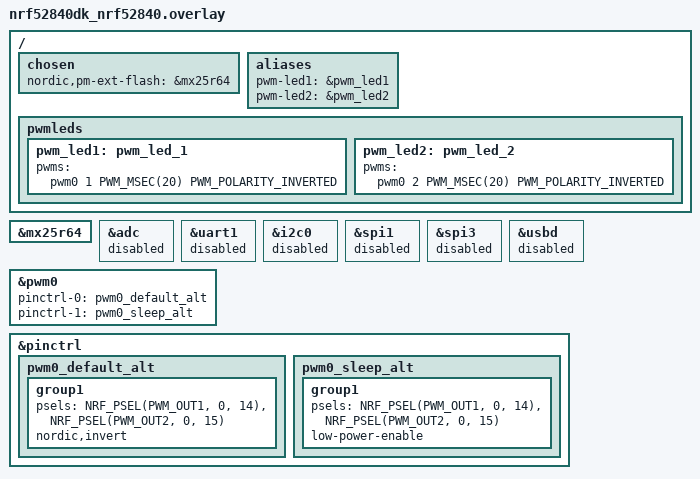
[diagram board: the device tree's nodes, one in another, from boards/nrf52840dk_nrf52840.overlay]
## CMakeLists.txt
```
#
# Smart window covering with Memfault observability over nRF Cloud CoAP.
# nRF52840 — based on the NCS matter/window_covering sample.
#

cmake_minimum_required(VERSION 3.20.0)

find_package(Zephyr HINTS $ENV{ZEPHYR_BASE})

project(blinds-nrf52840)

# Enable GNU STD support.
include(${ZEPHYR_CONNECTEDHOMEIP_MODULE_DIR}/config/nrfconnect/app/enable-gnu-std.cmake)

# Include all source files that are located in the Matter common directory.
include(${ZEPHYR_NRF_MODULE_DIR}/samples/matter/common/cmake/source_common.cmake)

# Include Data Model utils
include(${ZEPHYR_NRF_MODULE_DIR}/samples/matter/common/cmake/data_model.cmake)

include(${ZEPHYR_NRF_MODULE_DIR}/samples/matter/common/cmake/zap_helpers.cmake)
ncs_get_zap_parent_dir(ZAP_PARENT_DIR)

# src/ must be a global include so the Memfault SDK can find
# memfault_metrics_heartbeat_config.def and memfault_platform_config.h
zephyr_include_directories(src)

target_include_directories(app PRIVATE
  src
  ${ZAP_PARENT_DIR}
)

# --- Window covering application (from the NCS sample) ---
target_sources(app PRIVATE
  src/main.cpp
  src/app_task.cpp
  src/window_covering.cpp
  src/zcl_callbacks.cpp
)

# --- Observability stack ---
# Ported unchanged from openevse-nrf54l15 apart from blinds.cpp replacing the
# EVSE state source. Everything here is silicon-agnostic: OpenThread native UDP,
# mbedTLS DTLS, PSA crypto, no Zephyr IP stack.
target_sources(app PRIVATE
  src/blinds.cpp
  src/telemetry.c
  src/dtls_transport.c
  src/coap_codec.c
  src/jwt.c
  src/matter_metrics.cpp
  src/border_router.c
)

# nrfcloud_shell.c is nothing but shell command handlers, so it drops out of a
# release image entirely. jwt.c keeps its handlers behind #ifdef CONFIG_SHELL
# because the same file also holds jwt_generate_psa() and sntp_sync(), which
# the telemetry thread needs.
if(CONFIG_SHELL)
  target_sources(app PRIVATE src/nrfcloud_shell.c)
endif()

if(CONFIG_BLINDS_UDP_ECHO_SHELL)
  target_sources(app PRIVATE src/udp_echo_shell.c)
endif()

if(CONFIG_BLINDS_SIM)
  target_sources(app PRIVATE src/blinds_sim.cpp)
endif()

if(CONFIG_BLINDS_THREAD_AUTOJOIN)
  target_sources(app PRIVATE src/thread_prov.c)
endif()

if(CONFIG_PROVISIONING)
  target_sources(app PRIVATE
    src/provisioning.c
    src/provisioning_attest.cpp
    src/csr.c
  )
endif()

if(CONFIG_PROVISIONING_SHELL)
  target_sources(app PRIVATE src/provisioning_shell.c)
endif()

ncs_configure_data_model()
```

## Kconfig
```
mainmenu "Matter Window Covering with Memfault Observability (nRF52840)"

config STATE_LEDS
	bool "Use LEDs to indicate the device state"
	default y
	help
	  Use LEDs to render commissioning progress and factory reset initiation.

# Reduce Thread TX output power to 0 dBm for SED device
config OPENTHREAD_DEFAULT_TX_POWER
	default 0

menu "Observability"

config BLINDS_SIM
	bool "Simulate shade duty cycle"
	default n
	help
	  Drive the Matter WindowCovering cluster on a repeating daily schedule
	  so the blinds_* metrics carry realistic signal on a devkit with no
	  motor attached. Commands go through the same path a controller uses,
	  so the reported values are still live attribute reads.

	  Demo and pilot aid. Leave disabled in a production image.

config BLINDS_SIM_DAY_SECONDS
	int "Seconds of wall clock per simulated day"
	depends on BLINDS_SIM
	default 600
	help
	  A compressed day, so a dashboard fills with plausible duty cycle in
	  minutes rather than weeks. Four movements are spread across it.

config BLINDS_BUTTON_HEARTBEAT
	bool "Button 4 forces a heartbeat and an immediate upload"
	default y
	depends on MEMFAULT
	help
	  Collects a Memfault heartbeat and wakes the telemetry thread so the
	  chunk uploads within seconds instead of waiting out the upload
	  interval. Button 1 is the board function/factory-reset button and
	  buttons 2 and 3 are open/close, so button 4 is the free one.

	  Invaluable for demos; harmless to ship.

config BLINDS_UDP_ECHO_SHELL
	bool "UDP echo shell commands"
	default y
	depends on SHELL
	help
	  Adds 'echo ipv6' / 'echo nat64' for probing whether a given border
	  router actually routes device traffic to the internet. This is the
	  fastest way to characterise a new gateway — keep it in lab images.

config BLINDS_THREAD_AUTOJOIN
	bool "Auto-join Thread from a built-in dataset"
	default n
	help
	  Developer convenience: join a known Thread network at boot without
	  BLE commissioning. Requires a real dataset in thread_prov.c, which
	  contains the network master key — never enable for a shipped image.

endmenu

menu "Device identity provisioning"

config PROVISIONING
	bool "On-die key generation and attested CSR"
	depends on SETTINGS
	# PKCS#10 CSR construction. MBEDTLS_X509_CSR_WRITE_C alone does not
	# build: it needs X509_CREATE_C, which in turn needs OID_C,
	# ASN1_WRITE_C, PK_PARSE_C and either MD_C or USE_PSA_CRYPTO
	# (mbedtls check_config.h:1034). USE_PSA_CRYPTO is required anyway for
	# mbedtls_pk_setup_opaque(), which is what keeps the private key inside
	# PSA while the CSR is being signed.
	# No mbedTLS X.509 write selects: the CSR is encoded directly in csr.c.
	# mbedtls_x509write_csr() needed mbedtls_pk_setup_opaque() to bind a
	# non-exportable PSA key, and mbedTLS 4.x (NCS 3.4.0 onward) removed the
	# public PK module. Encoding it ourselves drops six Kconfig dependencies
	# and is immune to that churn.
	select BASE64
	help
	  Generate the nRF Cloud identity keypair inside the device and emit a
	  PKCS#10 CSR signed by the Matter DAC key, instead of compiling a
	  private key into the image. See plans/identity-provisioning.md.

if PROVISIONING

config PROVISIONING_PSA_KEY_ID
	int "PSA persistent key ID for the device identity key"
	default 305419896

config PROVISIONING_KEY_IN_KMU
	bool "Store the identity key in hardware KMU slots (nRF54L only)"
	default n
	help
	  Not available on nRF52840 — that part falls back to trusted storage
	  plus APPROTECT, which is the same protection the Matter DAC private
	  key already has. This symbol is what changes on migration to nRF54L.

config PROVISIONING_FALLBACK_KEY
	bool "Fall back to the compiled-in key in credentials.h"
	default n
	help
	  Set to n for production. With this enabled an unprovisioned unit still
	  has a usable identity, which is exactly what a shipped image must not.

config PROVISIONING_SHELL
	bool "Factory fixture shell commands"
	default y
	depends on SHELL

endif # PROVISIONING

endmenu

#
# mbedTLS DTLS client layer.
#
# nrf/subsys/net/openthread/Kconfig.defconfig forces MBEDTLS_SSL_TLS_C and
# MBEDTLS_SSL_CLI_C to 'n' unless one of OPENTHREAD_JOINER, COMMISSIONER,
# COAPS or BLE_TCAT is enabled. MBEDTLS_SSL_TLS_C is promptless, so prj.conf
# cannot raise it — the value comes purely from whichever 'default' is parsed
# first. These definitions precede the sourced NCS Kconfig files, so they win.
#
# The nRF54L project got here via CONFIG_OPENTHREAD_COAPS=y. That is not an
# option on nRF52840: the prebuilt MTD library exports no otCoapSecure symbols.
# We never use OpenThread's CoAP stack anyway — all traffic goes through the
# native UDP API — so overriding the two symbols directly is both cheaper and
# more honest about what is actually needed.
#
# NCS 3.4.0 made MBEDTLS_TLS_LIBRARY promptless as well, so it can no longer be
# set from prj.conf either. It is now selected only by the same Thread features
# listed above, by the Wi-Fi hostap_crypto stack, or by NET_SOCKETS_SOCKOPT_TLS
# (which drags in the Zephyr IP stack we deliberately avoid). On 3.2.x/3.3.x it
# still carries a prompt, so a default here is harmless there and required here.
config MBEDTLS_TLS_LIBRARY
	default y

config MBEDTLS_SSL_TLS_C
	default y

config MBEDTLS_SSL_CLI_C
	default y

# Work around an upstream defect in the NCS Memfault integration.
#
# nrf/modules/memfault-firmware-sdk/Kconfig defaults this prefix to
# "$(APP_VERSION_STRING)+", but Zephyr's kconfig.cmake exports the app version
# as APPVERSION -- APP_VERSION_STRING is never placed in the Kconfig
# environment. The reference therefore expands to nothing and every build
# reports a version of "+<build id>", losing the semantic part entirely. The
# sibling MEMFAULT_NCS_FW_VERSION uses APP_VERSION_TWEAK_STRING, which *is*
# exported, so only the AUTO path is affected.
#
# This default is evaluated before the module's because the application Kconfig
# is the top-level file. Remove it once NCS is fixed.
config MEMFAULT_NCS_FW_VERSION_PREFIX
	default "$(APPVERSION)+"

source "$(ZEPHYR_CONNECTEDHOMEIP_MODULE_DIR)/config/nrfconnect/chip-module/Kconfig.features"
source "$(ZEPHYR_CONNECTEDHOMEIP_MODULE_DIR)/config/nrfconnect/chip-module/Kconfig.defaults"
source "$(ZEPHYR_NRF_MODULE_DIR)/samples/matter/common/src/Kconfig"
source "Kconfig.zephyr"
```

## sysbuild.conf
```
#
# Copyright (c) 2024 Nordic Semiconductor
#
# SPDX-License-Identifier: LicenseRef-Nordic-5-Clause
#

SB_CONFIG_MATTER=y

# NCS 3.4.0: Matter partitions come from devicetree, not Partition Manager.
SB_CONFIG_PARTITION_MANAGER=n
```

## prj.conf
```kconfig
#
# Smart window covering with Memfault observability over nRF Cloud CoAP.
# Target: nrf52840dk/nrf52840
#
# Base configuration follows the NCS matter/window_covering sample, including
# its MTD / SSED sleepy-device topology, because that is what a real motorised
# shade is. The observability stack is layered on top unchanged.
#

# ---------------- Matter ----------------
CONFIG_CHIP=y
CONFIG_CHIP_PROJECT_CONFIG="src/chip_project_config.h"
CONFIG_CHIP_DEVICE_PRODUCT_NAME="Smart Shade"
CONFIG_NCS_SAMPLE_MATTER_ZAP_FILE_PATH="${APPLICATION_CONFIG_DIR}/src/default_zap/window-app.zap"
CONFIG_CHIP_DEVICE_PRODUCT_ID=32784
# Window Covering (0x0202). Without this the device type defaults to
# 0xFFFF, which is not a valid Matter device type and shows up wrong in
# Basic Information and the DNS-SD TXT records.
CONFIG_CHIP_DEVICE_TYPE=514
CONFIG_STD_CPP17=y

# BLE commissioning — the path a real product uses
CONFIG_CHIP_ENABLE_PAIRING_AUTOSTART=y
CONFIG_CHIP_BLE_EXT_ADVERTISING=y
CONFIG_CHIP_BLE_ADVERTISING_DURATION=60
CONFIG_BT_DEVICE_NAME="SmartShade"

# Factory data. Required for provisioning: the DAC and PAI live here, and
# provisioning_attest.cpp needs them to vouch for the CSR.
CONFIG_CHIP_FACTORY_DATA=y
CONFIG_CHIP_FACTORY_DATA_BUILD=y

# ---------------- Thread: sleepy end device ----------------
# A shade is battery or mains-with-low-duty-cycle, not a router. MTD keeps both
# the OpenThread library and the RAM footprint smaller than FTD.
CONFIG_OPENTHREAD_NORDIC_LIBRARY_MTD=y
CONFIG_OPENTHREAD_MTD=y
CONFIG_OPENTHREAD_FTD=n
CONFIG_CHIP_ENABLE_ICD_SUPPORT=y
CONFIG_CHIP_THREAD_SSED=y
CONFIG_CHIP_ICD_SLOW_POLL_INTERVAL=500
CONFIG_CHIP_ICD_FAST_POLLING_INTERVAL=500

# DNS client, for resolving nRF Cloud and the SNTP server through the border
# router. Verified present in the nRF52840 MTD prebuilt library.
CONFIG_OPENTHREAD_DNS_CLIENT=y

CONFIG_PWM=y
CONFIG_DK_LIBRARY=y
CONFIG_PM_DEVICE=y
CONFIG_IEEE802154_NRF5_RX_STACK_SIZE=1024
CONFIG_THREAD_NAME=y
CONFIG_MPU_STACK_GUARD=y
CONFIG_RESET_ON_FATAL_ERROR=n

# ---------------- Shell (lab build) ----------------
CONFIG_CHIP_LIB_SHELL=y
CONFIG_NCS_SAMPLE_MATTER_TEST_SHELL=y
CONFIG_OPENTHREAD_SHELL=y
CONFIG_SHELL_STACK_SIZE=10240
CONFIG_SHELL_CMD_BUFF_SIZE=512
CONFIG_USE_SEGGER_RTT=n
CONFIG_CHIP_NFC_ONBOARDING_PAYLOAD=n

# ---------------- DTLS transport ----------------
# NOTE: the nRF54L project reached this config via CONFIG_OPENTHREAD_COAPS=y,
# which is NOT usable here — the nRF52840 MTD prebuilt library exports no
# otCoapSecure symbols. The mbedTLS DTLS client is therefore selected directly.
# We never use OpenThread's CoAP stack anyway; this only ever supplied the
# mbedTLS configuration.
CONFIG_MBEDTLS=y
# MBEDTLS_TLS_LIBRARY is NOT set here: NCS 3.4.0 made it promptless, so
# assigning it in prj.conf is a hard Kconfig error. It is forced on in
# Kconfig instead, which works on 3.2.x, 3.3.x and 3.4.x alike.
CONFIG_MBEDTLS_SSL_PROTO_DTLS=y
# MBEDTLS_SSL_TLS_C / SSL_CLI_C are forced on in Kconfig — see the comment
# there. No SSL_SRV_C or SSL_COOKIE_C: this is a client only.
CONFIG_MBEDTLS_MD_C=y
CONFIG_MBEDTLS_KEY_EXCHANGE_ECDHE_ECDSA_ENABLED=y
# The nRF Cloud root CA in credentials.h is a PEM string. nrf_security leaves
# PEM_PARSE_C off under NCS 3.4.0, so mbedtls_x509_crt_parse() reads the PEM
# text as DER and fails with -0x2180 (X509_INVALID_FORMAT).
CONFIG_MBEDTLS_PEM_PARSE_C=y

# DTLS Connection ID (RFC 9146) — required by nRF Cloud CoAP
CONFIG_MBEDTLS_SSL_DTLS_CONNECTION_ID=y

# Handshake buffers. The 900-byte default cannot hold nRF Cloud's server cert.
CONFIG_MBEDTLS_SSL_IN_CONTENT_LEN=1500
CONFIG_MBEDTLS_SSL_OUT_CONTENT_LEN=900
CONFIG_MBEDTLS_HEAP_SIZE=20480

CONFIG_BASE64=y

# ---------------- Device identity provisioning ----------------
CONFIG_PROVISIONING=y
CONFIG_PROVISIONING_SHELL=y
# Lab devices only. Production images must set this to n.
CONFIG_PROVISIONING_FALLBACK_KEY=n
# nRF54L only — the one symbol that changes on migration.
# CONFIG_PROVISIONING_KEY_IN_KMU=y

# Persistent PSA keys need an encrypted ITS backend. nRF52840 has no TF-M, so
# this is the trusted_storage library rather than a secure partition.
CONFIG_SETTINGS=y
CONFIG_TRUSTED_STORAGE=y

# ---------------- Observability ----------------
CONFIG_BLINDS_UDP_ECHO_SHELL=y
CONFIG_BLINDS_THREAD_AUTOJOIN=n

CONFIG_MEMFAULT=y
CONFIG_MEMFAULT_SHELL=y
CONFIG_MEMFAULT_METRICS=y
CONFIG_MEMFAULT_LOGGING_ENABLE=n
CONFIG_MEMFAULT_NCS_PROJECT_KEY="YOUR_MEMFAULT_PROJECT_KEY"
# Firmware version: generated, not hand-maintained.
#
# MEMFAULT_NCS_FW_VERSION_AUTO reports "<APP_VERSION_STRING>+<build id prefix>",
# e.g. "0.2.0+fd7322", taking the semantic part from the VERSION file and the
# suffix from the GNU build ID. Four builds in two days previously all reported
# "0.1.0", including firmware that crash-looped every heartbeat and firmware
# that did not, which makes any crash-free-hours comparison across that boundary
# meaningless. Bump VERSION for a release; the build ID distinguishes every
# build in between for free.
CONFIG_MEMFAULT_NCS_FW_VERSION_AUTO=y
# Device ID and hardware version are board-specific: see boards/<board>.conf.
CONFIG_MEMFAULT_NCS_FW_TYPE="blinds-matter-software"
CONFIG_MEMFAULT_METRICS_MEMORY_USAGE=n
CONFIG_MEMFAULT_METRICS_SYNC_SUCCESS=n
CONFIG_MEMFAULT_METRICS_CONNECTIVITY_CONNECTED_TIME=n
CONFIG_MEMFAULT_METRICS_BLUETOOTH=n
CONFIG_MEMFAULT_NCS_IMPLEMENT_METRICS_COLLECTION=n

# Coredump lives in RAM. 4 KB rather than the nRF54L project's 8 KB — RAM is
# the scarce resource on a 256 KB part. Revisit once the real figure is known;
# a flash-backed coredump in the external QSPI is the alternative.
CONFIG_MEMFAULT_RAM_BACKED_COREDUMP=y
CONFIG_MEMFAULT_RAM_BACKED_COREDUMP_SIZE=4096

# Heartbeat every 30 min; a shade's state changes slowly and radio time is
# the dominant energy cost on a sleepy device.
# 300 s for the pilot: denser dashboards for demos. Raise for production —
# the energy cost per heartbeat is still unmeasured.
# Heartbeat collection reaches into OpenThread and the CHIP stack. The stock
# Zephyr port runs the collect callback on the system workqueue (1120-byte
# stack here), which overflows and faults instead of emitting a heartbeat.
# telemetry.c supplies the timer instead and collects on its own 8 KB thread.
CONFIG_MEMFAULT_METRICS_TIMER_CUSTOM=y
CONFIG_MEMFAULT_METRICS_HEARTBEAT_INTERVAL_SECS=300

# ---------------- Logging ----------------
CONFIG_LOG=y
CONFIG_LOG_MODE_DEFERRED=y
CONFIG_CHIP_APP_LOG_LEVEL=3
CONFIG_MATTER_LOG_LEVEL_INF=y

# ---------------- nRF52840 external flash ----------------
# The MCUboot secondary slot lives in the QSPI part, which is what frees the
# app slot to 959 KB. Also the natural home for a flash-backed coredump.
CONFIG_NORDIC_QSPI_NOR=y
CONFIG_NORDIC_QSPI_NOR_FLASH_LAYOUT_PAGE_SIZE=4096
CONFIG_STREAM_FLASH=y
CONFIG_IMG_MANAGER=y
CONFIG_MCUBOOT_IMG_MANAGER=y

# Simulated shade duty cycle so the blinds_* metrics carry signal on a DK.
CONFIG_BLINDS_SIM=y
```

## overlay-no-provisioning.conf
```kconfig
# Observability only, no on-die identity provisioning.
# Use with the base prj.conf to measure what the CSR/X509-write machinery costs:
#   west build -- -DEXTRA_CONF_FILE=overlay-no-provisioning.conf
CONFIG_PROVISIONING=n
CONFIG_PROVISIONING_SHELL=n
```

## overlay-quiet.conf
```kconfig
#
# Quiet the device for tooling that drives the shell.
#
# provision.py reads a command's output until the link goes idle. The blinds
# simulation logs every cluster write continuously, so the link never goes
# idle, the 'OK' is buried in a flood of ZCL traffic and provisioning fails
# with a misleading "did not emit" error. Provisioning is a factory step and
# the simulation has no business running during it.
#
CONFIG_BLINDS_SIM=n

# Let the shell change log levels at runtime, so the next person has a way out
# without a rebuild.
CONFIG_LOG_CMDS=y
```

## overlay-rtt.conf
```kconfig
#
# Console and shell over SEGGER RTT instead of the board UART.
#
# The nRF5340-DK's Interface MCU stopped passing VCOM traffic: the app core
# demonstrably transmits (UARTE0 EVENTS_TXSTARTED and EVENTS_ENDTX both set,
# PSEL.TXD = P0.20 as the devicetree specifies) but the host receives nothing
# on either virtual COM port. RTT rides the debug probe's memory access, which
# still works, so this gets a console back without waiting on a probe firmware
# repair.
#
# Layer it on:
#   west build -b nrf5340dk/nrf5340/cpuapp -- -DEXTRA_CONF_FILE=overlay-rtt.conf
#
CONFIG_USE_SEGGER_RTT=y
CONFIG_RTT_CONSOLE=y
CONFIG_UART_CONSOLE=n

# The standalone RTT log backend and the RTT shell backend both claim RTT
# channel 0, which is a build-time assertion failure. Let logs ride the shell's
# own log backend instead -- the same arrangement the UART console used.
CONFIG_LOG_BACKEND_RTT=n
CONFIG_LOG_BACKEND_UART=n
CONFIG_SHELL_LOG_BACKEND=y

CONFIG_SHELL_BACKEND_SERIAL=n
CONFIG_SHELL_BACKEND_RTT=y

# RTT defaults to SEGGER_RTT_MODE_NO_BLOCK_SKIP: when the up-buffer fills it
# discards output rather than waiting. That is invisible for logging but
# corrupts anything used as a data channel -- provision.py's attested CSR
# bundle (DAC, PAI, CSR and signature, several KB emitted in one burst) came
# back with whole blocks missing, which surfaces as the same misleading
# "device did not emit" error as a malformed argument.
#
# Blocking mode stalls the firmware whenever no host is draining RTT, so this
# belongs to a bench image only. Never ship it.
CONFIG_SEGGER_RTT_MODE_BLOCK_IF_FIFO_FULL=y
CONFIG_SEGGER_RTT_BUFFER_SIZE_UP=8192

# The host->target buffer defaults to 16 bytes, against a 512-byte shell command
# buffer. The RTT down-channel has no flow control back to the host, so a line
# written in one burst is simply truncated at 16 characters: "provision status"
# arrives as "provision sta". That surfaces as "Please specify a subcommand" or,
# worse, as a command that silently does something else. 'provision keygen' is
# exactly 16 characters, which is why it was the only step that ever worked.
# Match the shell buffer.
CONFIG_SEGGER_RTT_BUFFER_SIZE_DOWN=512
```

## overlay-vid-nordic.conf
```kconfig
# Diagnostic overlay: advertise Nordic's real CSA vendor ID (0x1915 = 6421) in
# place of the Matter test VID 0xFFF1 (65521), to establish whether an ecosystem
# refuses this device before opening a BLE connection purely on a vendor-ID
# lookup.
#
# Nordic permits use of its VID without guarantees, which is why this uses
# 0x1915 rather than an unrelated certified vendor's ID.
#
# The SDK only ships development DACs for VID 0xFFF1, and a real vendor's DAC
# would have to chain to that vendor's PAA, so the attestation credentials are
# pinned explicitly to the FFF1-8010 development set rather than letting the
# factory data generator look up a (nonexistent) 1915-8010 pair.
#
# The result is deliberately inconsistent: the advertisement, QR payload and
# Basic Information cluster all report 0x1915 while the DAC still attests
# 0xFFF1, so device attestation WILL fail once a commissioner connects. That is
# expected and does not invalidate the test -- the signal is whether a CHIPoBLE
# connection is opened at all, not whether commissioning completes.
#
# Bench diagnostic only. Never ship this.
CONFIG_CHIP_DEVICE_VENDOR_ID=6421

CONFIG_CHIP_FACTORY_DATA_CERT_SOURCE_USER=y
CONFIG_CHIP_FACTORY_DATA_USER_CERTS_DAC_CERT="/opt/nordic/ncs/v3.4.0/modules/lib/matter/credentials/development/attestation/Matter-Development-DAC-FFF1-8010-Cert.der"
CONFIG_CHIP_FACTORY_DATA_USER_CERTS_DAC_KEY="/opt/nordic/ncs/v3.4.0/modules/lib/matter/credentials/development/attestation/Matter-Development-DAC-FFF1-8010-Key.der"
CONFIG_CHIP_FACTORY_DATA_USER_CERTS_PAI_CERT="/opt/nordic/ncs/v3.4.0/modules/lib/matter/credentials/development/attestation/Matter-Development-PAI-FFF1-noPID-Cert.der"
```

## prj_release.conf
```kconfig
#
# Production image. Same application and observability stack as prj.conf, with
# every development affordance removed.
#
# Note on provisioning: PROVISIONING stays enabled (the device still needs its
# on-die key and JWT signing) but PROVISIONING_SHELL is off, so a fielded unit
# cannot be asked to re-key over a console. Factory provisioning therefore runs
# against a separate build that keeps the shell — see
# plans/identity-provisioning.md.
#

# ---------------- Matter ----------------
CONFIG_CHIP=y
CONFIG_CHIP_PROJECT_CONFIG="src/chip_project_config.h"
CONFIG_CHIP_DEVICE_PRODUCT_NAME="Smart Shade"
CONFIG_NCS_SAMPLE_MATTER_ZAP_FILE_PATH="${APPLICATION_CONFIG_DIR}/src/default_zap/window-app.zap"
CONFIG_CHIP_DEVICE_PRODUCT_ID=32784
# Window Covering (0x0202). Without this the device type defaults to
# 0xFFFF, which is not a valid Matter device type and shows up wrong in
# Basic Information and the DNS-SD TXT records.
CONFIG_CHIP_DEVICE_TYPE=514
CONFIG_STD_CPP17=y
CONFIG_CHIP_ENABLE_PAIRING_AUTOSTART=y
CONFIG_CHIP_BLE_EXT_ADVERTISING=y
CONFIG_CHIP_BLE_ADVERTISING_DURATION=60
CONFIG_BT_DEVICE_NAME="SmartShade"
CONFIG_CHIP_FACTORY_DATA=y
CONFIG_CHIP_FACTORY_DATA_BUILD=y
CONFIG_CHIP_NFC_ONBOARDING_PAYLOAD=n

# ---------------- Thread: sleepy end device ----------------
CONFIG_OPENTHREAD_NORDIC_LIBRARY_MTD=y
CONFIG_OPENTHREAD_MTD=y
CONFIG_OPENTHREAD_FTD=n
CONFIG_CHIP_ENABLE_ICD_SUPPORT=y
CONFIG_CHIP_THREAD_SSED=y
CONFIG_CHIP_ICD_SLOW_POLL_INTERVAL=500
CONFIG_CHIP_ICD_FAST_POLLING_INTERVAL=500
CONFIG_OPENTHREAD_DNS_CLIENT=y

CONFIG_PWM=y
CONFIG_DK_LIBRARY=y
CONFIG_PM_DEVICE=y
CONFIG_RAM_POWER_DOWN_LIBRARY=y
CONFIG_IEEE802154_NRF5_RX_STACK_SIZE=1024
CONFIG_MPU_STACK_GUARD=y
CONFIG_RESET_ON_FATAL_ERROR=y
CONFIG_NCS_SAMPLE_MATTER_WATCHDOG=y

# ---------------- DTLS transport ----------------
CONFIG_MBEDTLS=y
CONFIG_MBEDTLS_TLS_LIBRARY=y
CONFIG_MBEDTLS_MD_C=y
CONFIG_MBEDTLS_SSL_PROTO_DTLS=y
CONFIG_MBEDTLS_KEY_EXCHANGE_ECDHE_ECDSA_ENABLED=y
# The nRF Cloud root CA in credentials.h is a PEM string. nrf_security leaves
# PEM_PARSE_C off under NCS 3.4.0, so mbedtls_x509_crt_parse() reads the PEM
# text as DER and fails with -0x2180 (X509_INVALID_FORMAT).
CONFIG_MBEDTLS_PEM_PARSE_C=y
CONFIG_MBEDTLS_SSL_DTLS_CONNECTION_ID=y
CONFIG_MBEDTLS_SSL_IN_CONTENT_LEN=1500
CONFIG_MBEDTLS_SSL_OUT_CONTENT_LEN=900
CONFIG_MBEDTLS_HEAP_SIZE=20480
CONFIG_BASE64=y

# ---------------- Identity ----------------
CONFIG_PROVISIONING=y
CONFIG_PROVISIONING_SHELL=n
CONFIG_PROVISIONING_FALLBACK_KEY=n
CONFIG_SETTINGS=y
CONFIG_TRUSTED_STORAGE=y

# ---------------- Observability ----------------
CONFIG_BLINDS_UDP_ECHO_SHELL=n
CONFIG_BLINDS_THREAD_AUTOJOIN=n

CONFIG_MEMFAULT=y
CONFIG_MEMFAULT_SHELL=n
CONFIG_MEMFAULT_METRICS=y
CONFIG_MEMFAULT_LOGGING_ENABLE=n
CONFIG_MEMFAULT_NCS_PROJECT_KEY="YOUR_MEMFAULT_PROJECT_KEY"
# Firmware version: generated, not hand-maintained.
#
# MEMFAULT_NCS_FW_VERSION_AUTO reports "<APP_VERSION_STRING>+<build id prefix>",
# e.g. "0.2.0+fd7322", taking the semantic part from the VERSION file and the
# suffix from the GNU build ID. Four builds in two days previously all reported
# "0.1.0", including firmware that crash-looped every heartbeat and firmware
# that did not, which makes any crash-free-hours comparison across that boundary
# meaningless. Bump VERSION for a release; the build ID distinguishes every
# build in between for free.
CONFIG_MEMFAULT_NCS_FW_VERSION_AUTO=y
# Device ID and hardware version are board-specific: see boards/<board>.conf.
CONFIG_MEMFAULT_NCS_FW_TYPE="blinds-matter-software"
CONFIG_MEMFAULT_METRICS_MEMORY_USAGE=n
CONFIG_MEMFAULT_METRICS_SYNC_SUCCESS=n
CONFIG_MEMFAULT_METRICS_CONNECTIVITY_CONNECTED_TIME=n
CONFIG_MEMFAULT_METRICS_BLUETOOTH=n
CONFIG_MEMFAULT_NCS_IMPLEMENT_METRICS_COLLECTION=n
CONFIG_MEMFAULT_RAM_BACKED_COREDUMP=y
CONFIG_MEMFAULT_RAM_BACKED_COREDUMP_SIZE=4096
# Heartbeat collection reaches into OpenThread and the CHIP stack. The stock
# Zephyr port runs the collect callback on the system workqueue (1120-byte
# stack here), which overflows and faults instead of emitting a heartbeat.
# telemetry.c supplies the timer instead and collects on its own 8 KB thread.
CONFIG_MEMFAULT_METRICS_TIMER_CUSTOM=y
CONFIG_MEMFAULT_METRICS_HEARTBEAT_INTERVAL_SECS=1800

# ---------------- Strip development affordances ----------------
CONFIG_CHIP_LIB_SHELL=n
CONFIG_NCS_SAMPLE_MATTER_TEST_SHELL=n
CONFIG_OPENTHREAD_SHELL=n
CONFIG_SHELL=n
CONFIG_CONSOLE=n
CONFIG_UART_CONSOLE=n
CONFIG_SERIAL=n
CONFIG_LOG=n
CONFIG_PRINTK=n
CONFIG_BOOT_BANNER=n
CONFIG_THREAD_NAME=n
CONFIG_ASSERT_VERBOSE=n
CONFIG_ASSERT_NO_FILE_INFO=y
CONFIG_USE_SEGGER_RTT=n

# LTO is deliberately OFF, unlike the NCS window_covering release config.
#
# The Memfault Zephyr port hooks fault handling through linker symbol
# interposition — -Wl,--wrap=z_arm_fault, --wrap=z_fatal_error, --wrap=main and
# others (ports/zephyr/common/CMakeLists.txt, ports/zephyr/panics/CMakeLists.txt).
# LTO internalises those symbols, so the linker can no longer interpose and the
# build dies with 'undefined reference to z_arm_fault' and
# 'undefined reference to __wrap_z_fatal_error'.
#
# Coredump capture is the whole point of the exercise, so LTO loses.
# CONFIG_LTO=y
CONFIG_ISR_TABLES_LOCAL_DECLARATION=y

# ---------------- nRF52840 external flash ----------------
CONFIG_NORDIC_QSPI_NOR=y
CONFIG_NORDIC_QSPI_NOR_FLASH_LAYOUT_PAGE_SIZE=4096
CONFIG_STREAM_FLASH=y
CONFIG_IMG_MANAGER=y
CONFIG_MCUBOOT_IMG_MANAGER=y
```

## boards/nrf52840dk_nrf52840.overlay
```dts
/* Copyright (c) 2021 Nordic Semiconductor ASA
 *
 * SPDX-License-Identifier: LicenseRef-Nordic-5-Clause
 */

/*
 * NCS 3.4.0 declares the Matter partition layout in devicetree rather than
 * Partition Manager. The addresses are identical to what
 * pm_static_nrf52840dk_nrf52840.yml declared on 3.2.x/3.3.x — only the
 * mechanism changed. For 3.2.x/3.3.x use -DFILE_SUFFIX=ncs32.
 */
#include <samples/matter/nrf52840_partitions.dtsi>

/ {
	chosen {
		nordic,pm-ext-flash = &mx25r64;
	};
};

&mx25r64 {
	status = "okay";
};

/ {
	/*
	 * Configure LED2 and LED3 to show the state of the
	 * window cover,by using the LED's brightness level.
	 */
	aliases {
		pwm-led1 = &pwm_led1;
		pwm-led2 = &pwm_led2;
	};

	pwmleds {
		pwm_led1: pwm_led_1 {
			pwms = <&pwm0 1 PWM_MSEC(20) PWM_POLARITY_INVERTED>;
		};

		pwm_led2: pwm_led_2 {
			pwms = <&pwm0 2 PWM_MSEC(20) PWM_POLARITY_INVERTED>;
		};
	};
};

/* Disable unused peripherals to reduce power consumption */
&adc {
	status = "disabled";
};

&uart1 {
	status = "disabled";
};

&i2c0 {
	status = "disabled";
};

&spi1 {
	status = "disabled";
};

&spi3 {
	status = "disabled";
};

&usbd {
	status = "disabled";
};

&pwm0 {
	pinctrl-0 = <&pwm0_default_alt>;
	pinctrl-1 = <&pwm0_sleep_alt>;
	pinctrl-names = "default", "sleep";
};

&pinctrl {
	pwm0_default_alt: pwm0_default_alt {
		group1 {
			psels = <NRF_PSEL(PWM_OUT1, 0, 14)>, <NRF_PSEL(PWM_OUT2, 0, 15)>;
			nordic,invert;
		};
	};

	pwm0_sleep_alt: pwm0_sleep_alt {
		group1 {
			psels = <NRF_PSEL(PWM_OUT1, 0, 14)>, <NRF_PSEL(PWM_OUT2, 0, 15)>;
			low-power-enable;
		};
	};
};
```

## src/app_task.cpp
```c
/*
 * Copyright (c) 2022 Nordic Semiconductor ASA
 *
 * SPDX-License-Identifier: LicenseRef-Nordic-5-Clause
 */

#include "app_task.h"

#include "window_covering.h"
#include "matter_metrics.h"
#ifdef CONFIG_BLINDS_BUTTON_HEARTBEAT
#include "telemetry.h"
#include <memfault/metrics/metrics.h>
#endif

#include "app/matter_init.h"
#include "app/task_executor.h"
#include "clusters/identify.h"

#include <setup_payload/OnboardingCodesUtil.h>

#include <zephyr/logging/log.h>

LOG_MODULE_DECLARE(app, CONFIG_CHIP_APP_LOG_LEVEL);

using namespace ::chip;
using namespace ::chip::app;
using namespace ::chip::DeviceLayer;

namespace
{
Nrf::Matter::IdentifyCluster sIdentifyCluster(WindowCovering::Endpoint());

#define OPEN_BUTTON_MASK DK_BTN2_MSK
#define CLOSE_BUTTON_MASK DK_BTN3_MSK

/*
 * Button 1 is the board library's function/factory-reset button and buttons 2
 * and 3 are open/close, so button 4 is the one left. It forces a heartbeat and
 * wakes the telemetry thread, which turns a demo from "wait out the upload
 * interval" into "press this and watch the dashboard".
 */
#ifdef CONFIG_BLINDS_BUTTON_HEARTBEAT
#define HEARTBEAT_BUTTON_MASK DK_BTN4_MSK
#endif
} /* namespace */

void AppTask::ButtonEventHandler(Nrf::ButtonState state, Nrf::ButtonMask hasChanged)
{
	if (OPEN_BUTTON_MASK & hasChanged) {
		WindowButtonAction action =
			(OPEN_BUTTON_MASK & state) ? WindowButtonAction::Pressed : WindowButtonAction::Released;
		Nrf::PostTask([action] { OpenHandler(action); });
	}

#ifdef CONFIG_BLINDS_BUTTON_HEARTBEAT
	if ((HEARTBEAT_BUTTON_MASK & hasChanged) && (HEARTBEAT_BUTTON_MASK & state)) {
		/*
		 * Collection reaches into OpenThread and the CHIP stack, and
		 * this runs on the system workqueue, so hand it to the
		 * telemetry thread rather than doing it here.
		 */
		telemetry_request_heartbeat();
		LOG_INF("Heartbeat triggered by button; uploading now");
	}
#endif

	if (CLOSE_BUTTON_MASK & hasChanged) {
		WindowButtonAction action =
			(CLOSE_BUTTON_MASK & state) ? WindowButtonAction::Pressed : WindowButtonAction::Released;
		Nrf::PostTask([action] { CloseHandler(action); });
	}
}

void AppTask::OpenHandler(const WindowButtonAction &action)
{
	if (action == WindowButtonAction::Pressed) {
		Instance().mOpenButtonIsPressed = true;
		if (Instance().mCloseButtonIsPressed) {
			Instance().ToggleMoveType();
		}
	} else {
		if (!Instance().mCloseButtonIsPressed) {
			if (!Instance().mMoveTypeRecentlyChanged) {
				WindowCovering::Instance().SetSingleStepTarget(OperationalState::MovingUpOrOpen);
			} else {
				Instance().mMoveTypeRecentlyChanged = false;
			}
		}
		Instance().mOpenButtonIsPressed = false;
	}
}

void AppTask::CloseHandler(const WindowButtonAction &action)
{
	if (action == WindowButtonAction::Pressed) {
		Instance().mCloseButtonIsPressed = true;
		if (Instance().mOpenButtonIsPressed) {
			Instance().ToggleMoveType();
		}
	} else {
		if (!Instance().mOpenButtonIsPressed) {
			if (!Instance().mMoveTypeRecentlyChanged) {
				WindowCovering::Instance().SetSingleStepTarget(OperationalState::MovingDownOrClose);
			} else {
				Instance().mMoveTypeRecentlyChanged = false;
			}
		}
		Instance().mCloseButtonIsPressed = false;
	}
}

void AppTask::ToggleMoveType()
{
	if (WindowCovering::Instance().GetMoveType() == WindowCovering::MoveType::LIFT) {
		WindowCovering::Instance().SetMoveType(WindowCovering::MoveType::TILT);
		LOG_INF("Window covering move: tilt");
	} else {
		WindowCovering::Instance().SetMoveType(WindowCovering::MoveType::LIFT);
		LOG_INF("Window covering move: lift");
	}
	mMoveTypeRecentlyChanged = true;
}

CHIP_ERROR AppTask::Init()
{
	/* Initialize Matter stack */
	ReturnErrorOnFailure(Nrf::Matter::PrepareServer(Nrf::Matter::InitData{ .mPostServerInitClbk = [] {
		WindowCovering::Instance().PositionLEDUpdate(WindowCovering::MoveType::LIFT);
		WindowCovering::Instance().PositionLEDUpdate(WindowCovering::MoveType::TILT);
		return CHIP_NO_ERROR;
	} }));

	if (!Nrf::GetBoard().Init(ButtonEventHandler)) {
		LOG_ERR("User interface initialization failed.");
		return CHIP_ERROR_INCORRECT_STATE;
	}

	/* Register Matter event handler that controls the connectivity status LED based on the captured Matter network
	 * state. */
	ReturnErrorOnFailure(Nrf::Matter::RegisterEventHandler(Nrf::Board::DefaultMatterEventHandler, 0));

	ReturnErrorOnFailure(sIdentifyCluster.Init());

	/*
	 * Thread/Matter diagnostics collection. Registers the event handler that
	 * counts commissioning completions and, at heartbeat time, snapshots
	 * fabric health and the administrator's vendor ID — the field that lets
	 * fleet metrics be sliced by ecosystem.
	 */
	matter_metrics_init();

	return Nrf::Matter::StartServer();
}

CHIP_ERROR AppTask::StartApp()
{
	ReturnErrorOnFailure(Init());

	while (true) {
		Nrf::DispatchNextTask();
	}

	return CHIP_NO_ERROR;
}
```

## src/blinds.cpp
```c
/*
 * Copyright (c) 2026 Jon Sharp
 *
 * SPDX-License-Identifier: Apache-2.0
 */

/*
 * Observability view of the window covering — reads live Matter attributes.
 * See blinds.h.
 */

#include "blinds.h"

#include <zephyr/kernel.h>
#include <zephyr/sys/atomic.h>

#include <platform/CHIPDeviceLayer.h>
#include <app/clusters/window-covering-server/window-covering-server.h>
#include <app-common/zap-generated/attributes/Accessors.h>

using namespace chip;
using namespace chip::app::Clusters;
using chip::Protocols::InteractionModel::Status;

namespace {

constexpr EndpointId kCoveringEndpoint = 1;

atomic_t s_move_count;
atomic_t s_stall_count;

/*
 * Position attributes are nullable: null means the covering does not know
 * where it is. That is a meaningful state rather than an error, so it is
 * reported as UINT16_MAX instead of being coerced to 0.
 */
uint16_t ReadPercent100ths(
	Status (*getter)(EndpointId, app::DataModel::Nullable<Percent100ths> &))
{
	app::DataModel::Nullable<Percent100ths> value;

	if (getter(kCoveringEndpoint, value) != Status::Success || value.IsNull()) {
		return UINT16_MAX;
	}

	return value.Value();
}

blinds_motion_t DecodeMotion(uint8_t status, uint8_t shift)
{
	/* OperationalStatus packs global/lift/tilt into 2-bit fields. */
	switch ((status >> shift) & 0x03) {
	case 1:
		return BLINDS_MOTION_OPENING;
	case 2:
		return BLINDS_MOTION_CLOSING;
	default:
		return BLINDS_MOTION_STALLED;
	}
}

} /* namespace */

void blinds_get_data(struct blinds_data *out)
{
	if (out == nullptr) {
		return;
	}

	*out = {};
	out->lift_position = UINT16_MAX;
	out->tilt_position = UINT16_MAX;
	out->lift_target = UINT16_MAX;
	out->tilt_target = UINT16_MAX;

	DeviceLayer::PlatformMgr().LockChipStack();

	out->lift_position =
		ReadPercent100ths(WindowCovering::Attributes::CurrentPositionLiftPercent100ths::Get);
	out->tilt_position =
		ReadPercent100ths(WindowCovering::Attributes::CurrentPositionTiltPercent100ths::Get);
	out->lift_target =
		ReadPercent100ths(WindowCovering::Attributes::TargetPositionLiftPercent100ths::Get);
	out->tilt_target =
		ReadPercent100ths(WindowCovering::Attributes::TargetPositionTiltPercent100ths::Get);

	BitMask<WindowCovering::OperationalStatus> status;
	if (WindowCovering::Attributes::OperationalStatus::Get(kCoveringEndpoint, &status) ==
	    Status::Success) {
		out->lift_motion = DecodeMotion(status.Raw(), 2);
		out->tilt_motion = DecodeMotion(status.Raw(), 4);
	}

	BitMask<WindowCovering::ConfigStatus> config;
	if (WindowCovering::Attributes::ConfigStatus::Get(kCoveringEndpoint, &config) ==
	    Status::Success) {
		out->config_status = config.Raw();
		/* LiftPositionAware — set once the covering knows where it is. A
		 * unit that loses calibration in the field becomes a support
		 * call, so it is worth reporting on every heartbeat. */
		out->calibrated =
			config.Has(WindowCovering::ConfigStatus::kLiftPositionAware);
	}

	BitMask<WindowCovering::Mode> mode;
	if (WindowCovering::Attributes::Mode::Get(kCoveringEndpoint, &mode) == Status::Success) {
		out->mode = mode.Raw();
	}

	DeviceLayer::PlatformMgr().UnlockChipStack();
}

uint32_t blinds_take_move_count(void)
{
	return (uint32_t)atomic_set(&s_move_count, 0);
}

uint32_t blinds_take_stall_count(void)
{
	return (uint32_t)atomic_set(&s_stall_count, 0);
}

void blinds_record_move_start(void)
{
	atomic_inc(&s_move_count);
}

void blinds_record_stall(void)
{
	atomic_inc(&s_stall_count);
}
```

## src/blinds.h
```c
/*
 * Copyright (c) 2026 Jon Sharp
 *
 * SPDX-License-Identifier: Apache-2.0
 */

#pragma once

#include <stdint.h>
#include <stdbool.h>

#ifdef __cplusplus
extern "C" {
#endif

/*
 * Observability view of the window covering.
 *
 * Values are read from the live Matter WindowCovering cluster attributes
 * rather than from a simulation, so what Memfault reports is exactly what a
 * Matter controller sees. On a real product this file is the only thing that
 * changes when the motor driver replaces the sample's PWM indicators.
 */

/* Mirrors Matter OperationalStatus movement bits. */
typedef enum {
	BLINDS_MOTION_STALLED = 0,
	BLINDS_MOTION_OPENING = 1,
	BLINDS_MOTION_CLOSING = 2,
} blinds_motion_t;

struct blinds_data {
	/* Positions in hundredths of a percent (0 = open, 10000 = closed).
	 * UINT16_MAX means the attribute is null / position unknown. */
	uint16_t        lift_position;
	uint16_t        tilt_position;
	uint16_t        lift_target;
	uint16_t        tilt_target;

	blinds_motion_t lift_motion;
	blinds_motion_t tilt_motion;

	bool            calibrated;
	uint8_t         mode;           /* Matter Mode attribute bitmap */
	uint8_t         config_status;  /* Matter ConfigStatus bitmap */
};

/* Snapshot current covering state. Takes the CHIP stack lock internally. */
void blinds_get_data(struct blinds_data *out);

/* Cumulative movement counters, reset on read (heartbeat deltas). */
uint32_t blinds_take_move_count(void);
uint32_t blinds_take_stall_count(void);

/* Called from the window covering driver on state transitions. */
void blinds_record_move_start(void);
void blinds_record_stall(void);

#ifdef __cplusplus
}
#endif
```

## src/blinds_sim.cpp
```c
/*
 * Copyright (c) 2026 Jon Sharp
 *
 * SPDX-License-Identifier: Apache-2.0
 *
 * Simulated shade duty cycle. See blinds_sim.h.
 */

#include "blinds_sim.h"
#include "blinds.h"

#include <zephyr/kernel.h>
#include <zephyr/random/random.h>
#include <zephyr/sys/atomic.h>
#include <zephyr/logging/log.h>

#include <app-common/zap-generated/attributes/Accessors.h>
#include <app/clusters/window-covering-server/window-covering-server.h>
#include <platform/CHIPDeviceLayer.h>

#ifdef CONFIG_MEMFAULT
#include <memfault/core/trace_event.h>
#include <memfault/metrics/metrics.h>
#endif

LOG_MODULE_REGISTER(blinds_sim, LOG_LEVEL_INF);

using namespace chip;
using namespace chip::app::Clusters;

namespace
{

constexpr EndpointId kEndpoint = 1;

/* Positions are hundredths of a percent: 0 = fully open, 10000 = fully closed. */
constexpr uint16_t kOpen = 0;
constexpr uint16_t kClosed = 10000;

atomic_t s_travel_pct;
atomic_t s_obstructions;
atomic_t s_motor_current_ma;

/*
 * A compressed day. One simulated day per SIM_DAY_SEC of wall clock, so a
 * dashboard fills with plausible duty cycle in minutes rather than weeks.
 * Deliberately not 1:1 — this exists to exercise metrics, not to be a clock.
 */
constexpr int kSimDaySec = CONFIG_BLINDS_SIM_DAY_SECONDS;

struct SimStep {
	uint16_t    lift;       /* target lift position */
	uint16_t    tilt;       /* target tilt position */
	const char *label;
};

/*
 * A residential shade's actual day: open at breakfast, tilt against midday
 * sun, reopen in the afternoon, close at dusk. Four moves a day is roughly
 * 1,460 a year, which is the duty figure that matters for mechanical wear.
 */
const SimStep kDay[] = {
	{ kOpen,  2000, "morning open" },
	{ 3000,   7000, "midday sun" },
	{ kOpen,  3000, "afternoon" },
	{ kClosed, kClosed, "dusk close" },
};

uint32_t rand_range(uint32_t lo, uint32_t hi)
{
	if (hi <= lo) {
		return lo;
	}
	return lo + (sys_rand32_get() % (hi - lo + 1));
}

uint16_t current_lift()
{
	chip::app::DataModel::Nullable<chip::Percent100ths> pos;

	DeviceLayer::PlatformMgr().LockChipStack();
	WindowCovering::Attributes::CurrentPositionLiftPercent100ths::Get(kEndpoint, pos);
	DeviceLayer::PlatformMgr().UnlockChipStack();

	return pos.IsNull() ? kOpen : pos.Value();
}

/*
 * Issue a movement the way a controller would: write the target attribute and
 * let the sample's window covering driver run the motion. The resulting
 * OperationalStatus transitions are what blinds.cpp reports.
 */
void drive_to(uint16_t lift, uint16_t tilt)
{
	DeviceLayer::PlatformMgr().LockChipStack();
	WindowCovering::Attributes::TargetPositionLiftPercent100ths::Set(kEndpoint, lift);
	WindowCovering::Attributes::TargetPositionTiltPercent100ths::Set(kEndpoint, tilt);
	DeviceLayer::PlatformMgr().UnlockChipStack();
}

void sim_thread(void *, void *, void *)
{
	/* Let Matter finish initialising before writing attributes. */
	k_sleep(K_SECONDS(20));
	LOG_INF("Shade simulation started (%d s per simulated day)", kSimDaySec);

	size_t step = 0;

	while (true) {
		const SimStep &s = kDay[step % ARRAY_SIZE(kDay)];
		uint16_t from = current_lift();

		/*
		 * Movement session: one Memfault report per move. A binding
		 * mechanism shows up as peak current trending across thousands
		 * of units, which a heartbeat average would hide.
		 */
#ifdef CONFIG_MEMFAULT
		MEMFAULT_METRICS_SESSION_START(blinds_movement);
#endif
		int64_t t0 = k_uptime_get();

		blinds_record_move_start();
		drive_to(s.lift, s.tilt);

		/* Nominal shade speed: full travel in ~12 s. */
		uint32_t distance_pct =
			(uint32_t)((from > s.lift ? from - s.lift : s.lift - from) / 100);
		uint32_t travel_ms = 1200 + distance_pct * 120;

		/* Running current scales with load; add spread so trends exist. */
		uint32_t nominal_ma = rand_range(180, 240);
		uint32_t peak_ma = nominal_ma;
		uint32_t stalls = 0;

		atomic_set(&s_motor_current_ma, (atomic_val_t)nominal_ma);

		/*
		 * Fault injection. Rates chosen to be visible on a dashboard in
		 * an afternoon rather than to model a real failure distribution:
		 * roughly 1 move in 12 stalls, 1 in 25 hits an obstruction.
		 */
		bool will_stall = (rand_range(1, 12) == 1);
		bool will_obstruct = (rand_range(1, 25) == 1);

		if (will_stall) {
			stalls++;
			peak_ma = rand_range(400, 650);
			atomic_set(&s_motor_current_ma, (atomic_val_t)peak_ma);
			blinds_record_stall();
#ifdef CONFIG_MEMFAULT
			MEMFAULT_TRACE_EVENT_WITH_LOG(blinds_stall,
				"%s: stall at %u%%, %u mA", s.label,
				(unsigned)(from / 100), (unsigned)peak_ma);
			MEMFAULT_METRIC_SESSION_SET_UNSIGNED(move_stalls,
							     blinds_movement, stalls);
#endif
			LOG_WRN("simulated stall during %s (%u mA)", s.label,
				(unsigned)peak_ma);
		}

		if (will_obstruct) {
			atomic_inc(&s_obstructions);
			peak_ma = MAX(peak_ma, rand_range(500, 800));
			atomic_set(&s_motor_current_ma, (atomic_val_t)peak_ma);
#ifdef CONFIG_MEMFAULT
			MEMFAULT_TRACE_EVENT_WITH_LOG(blinds_obstruction,
				"%s: obstruction, %u mA", s.label,
				(unsigned)peak_ma);
#endif
			LOG_WRN("simulated obstruction during %s", s.label);
		}

		k_sleep(K_MSEC(travel_ms));

		atomic_add(&s_travel_pct, (atomic_val_t)distance_pct);
		atomic_set(&s_motor_current_ma, 0);

#ifdef CONFIG_MEMFAULT
		MEMFAULT_METRIC_SESSION_SET_UNSIGNED(
			move_duration_ms, blinds_movement,
			(uint32_t)(k_uptime_get() - t0));
		MEMFAULT_METRIC_SESSION_SET_UNSIGNED(
			move_distance_pct, blinds_movement, distance_pct);
		MEMFAULT_METRIC_SESSION_SET_UNSIGNED(
			move_peak_current_ma, blinds_movement, peak_ma);
		MEMFAULT_METRICS_SESSION_END(blinds_movement);
#endif

		step++;
		k_sleep(K_SECONDS(kSimDaySec / (int)ARRAY_SIZE(kDay)));
	}
}

} /* namespace */

uint32_t blinds_sim_motor_current_ma(void)
{
	return (uint32_t)atomic_get(&s_motor_current_ma);
}

uint32_t blinds_sim_take_travel_pct(void)
{
	return (uint32_t)atomic_set(&s_travel_pct, 0);
}

uint32_t blinds_sim_take_obstructions(void)
{
	return (uint32_t)atomic_set(&s_obstructions, 0);
}

K_THREAD_DEFINE(blinds_sim_tid, 4096, sim_thread, NULL, NULL, NULL,
		K_LOWEST_APPLICATION_THREAD_PRIO, 0, 0);
```

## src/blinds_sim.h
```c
/*
 * Copyright (c) 2026 Jon Sharp
 *
 * SPDX-License-Identifier: Apache-2.0
 */

#pragma once

#include <stdint.h>

#ifdef __cplusplus
extern "C" {
#endif

/*
 * Simulated shade behaviour, so the product metrics carry a realistic signal
 * on a devkit with no motor attached.
 *
 * It drives the real Matter WindowCovering cluster rather than writing metrics
 * directly: commands go through the same path a controller would use, so
 * blinds.cpp keeps reading live attributes and what Memfault reports is still
 * exactly what a Matter controller would see. Deleting this file changes
 * nothing else.
 */

/* Motor current for the most recent sample, mA. 0 when stalled/idle. */
uint32_t blinds_sim_motor_current_ma(void);

/* Cumulative travel in percent of full range, reset on read. */
uint32_t blinds_sim_take_travel_pct(void);

/* Obstruction trips, reset on read. */
uint32_t blinds_sim_take_obstructions(void);

#ifdef __cplusplus
}
#endif
```

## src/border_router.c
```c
/*
 * Copyright (c) 2026 Jon Sharp
 *
 * SPDX-License-Identifier: Apache-2.0
 *
 * Border router identification over Thread network diagnostics.
 * See border_router.h for why OUI lookup is not an option.
 */

#include "border_router.h"

#include <zephyr/kernel.h>
#include <zephyr/logging/log.h>

#include <openthread.h>
#include <openthread/dataset.h>
#include <openthread/netdiag.h>
#include <openthread/thread.h>

#include <string.h>

LOG_MODULE_REGISTER(border_router, LOG_LEVEL_INF);

/*
 * A diagnostics request is a real network round trip. On a sleepy end device
 * it also forces a wake, so this is deliberately infrequent: the answer only
 * changes when the parent changes, which is rare.
 */
#define QUERY_MIN_INTERVAL_MS (10 * 60 * 1000)

/* Response arrives on the OpenThread work queue; readers are the telemetry
 * thread and the shell. A mutex is enough — no ISR touches this. */
static K_MUTEX_DEFINE(s_lock);

static struct border_router_info s_info;
static int64_t s_last_query_ms;
static bool s_query_outstanding;

static const uint8_t s_tlv_types[] = {
	OT_NETWORK_DIAGNOSTIC_TLV_VENDOR_NAME,
	OT_NETWORK_DIAGNOSTIC_TLV_VENDOR_MODEL,
};

static void diag_response_cb(otError error, otMessage *message,
			     const otMessageInfo *message_info, void *context)
{
	ARG_UNUSED(message_info);
	ARG_UNUSED(context);

	k_mutex_lock(&s_lock, K_FOREVER);
	s_query_outstanding = false;

	if (error != OT_ERROR_NONE || message == NULL) {
		/*
		 * A gateway that does not answer is itself a result — some
		 * border routers do not implement the vendor TLVs. Record it
		 * rather than inventing a vendor.
		 */
		s_info.query_failures++;
		k_mutex_unlock(&s_lock);
		LOG_WRN("border router diagnostics failed: %d", error);
		return;
	}

	otNetworkDiagIterator iter = OT_NETWORK_DIAGNOSTIC_ITERATOR_INIT;
	otNetworkDiagTlv tlv;

	while (otThreadGetNextDiagnosticTlv(message, &iter, &tlv) == OT_ERROR_NONE) {
		switch (tlv.mType) {
		case OT_NETWORK_DIAGNOSTIC_TLV_VENDOR_NAME:
			strncpy(s_info.vendor_name, tlv.mData.mVendorName,
				sizeof(s_info.vendor_name) - 1);
			s_info.vendor_name[sizeof(s_info.vendor_name) - 1] = '\0';
			s_info.valid = true;
			break;
		case OT_NETWORK_DIAGNOSTIC_TLV_VENDOR_MODEL:
			strncpy(s_info.vendor_model, tlv.mData.mVendorModel,
				sizeof(s_info.vendor_model) - 1);
			s_info.vendor_model[sizeof(s_info.vendor_model) - 1] = '\0';
			s_info.valid = true;
			break;
		default:
			break;
		}
	}

	bool valid = s_info.valid;
	char name[BR_VENDOR_STR_MAX];
	char model[BR_VENDOR_STR_MAX];

	strcpy(name, s_info.vendor_name);
	strcpy(model, s_info.vendor_model);
	k_mutex_unlock(&s_lock);

	if (valid) {
		LOG_INF("border router: vendor=\"%s\" model=\"%s\"", name, model);
	} else {
		LOG_WRN("border router answered with no vendor TLVs");
	}
}

void border_router_query(void)
{
	otInstance *instance = openthread_get_default_instance();

	if (instance == NULL) {
		return;
	}

	int64_t now = k_uptime_get();

	k_mutex_lock(&s_lock, K_FOREVER);
	bool skip = s_query_outstanding ||
		    (s_last_query_ms != 0 &&
		     (now - s_last_query_ms) < QUERY_MIN_INTERVAL_MS);
	k_mutex_unlock(&s_lock);

	if (skip) {
		return;
	}

	openthread_mutex_lock();

	otRouterInfo parent;
	otError err = otThreadGetParentInfo(instance, &parent);
	otIp6Address dest;

	if (err == OT_ERROR_NONE) {
		/*
		 * Address the parent by its RLOC rather than a link-local
		 * address: the mesh-local prefix plus the RLOC16 locator is
		 * always routable from a child, whereas the parent's
		 * link-local address is not exposed by otRouterInfo.
		 */
		const otMeshLocalPrefix *ml = otThreadGetMeshLocalPrefix(instance);

		memset(&dest, 0, sizeof(dest));
		memcpy(dest.mFields.m8, ml->m8, OT_MESH_LOCAL_PREFIX_SIZE);
		dest.mFields.m8[8] = 0x00;
		dest.mFields.m8[9] = 0x00;
		dest.mFields.m8[10] = 0x00;
		dest.mFields.m8[11] = 0xff;
		dest.mFields.m8[12] = 0xfe;
		dest.mFields.m8[13] = 0x00;
		dest.mFields.m8[14] = (uint8_t)(parent.mRloc16 >> 8);
		dest.mFields.m8[15] = (uint8_t)(parent.mRloc16 & 0xff);

		err = otThreadSendDiagnosticGet(instance, &dest, s_tlv_types,
						ARRAY_SIZE(s_tlv_types),
						diag_response_cb, NULL);
	}

	openthread_mutex_unlock();

	k_mutex_lock(&s_lock, K_FOREVER);
	s_last_query_ms = now;
	if (err == OT_ERROR_NONE) {
		s_query_outstanding = true;
	} else {
		s_info.query_failures++;
	}
	k_mutex_unlock(&s_lock);

	if (err != OT_ERROR_NONE) {
		LOG_WRN("border router query not sent: %d", err);
	}
}

void border_router_get(struct border_router_info *out)
{
	if (out == NULL) {
		return;
	}

	k_mutex_lock(&s_lock, K_FOREVER);
	*out = s_info;
	k_mutex_unlock(&s_lock);
}
```
